VERSION ""

NS_ :

BS_ :

BU_ :

BO_ 1308 Rec_51C: 8 Vector__XXX

BO_ 1436 Rec_59C: 8 Vector__XXX

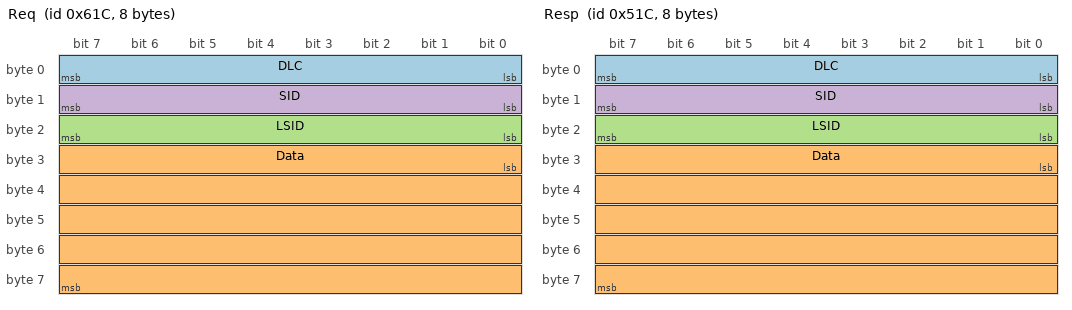
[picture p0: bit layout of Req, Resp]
BO_ 1564 Req: 8 Vector__XXX
  SG_ DLC : 0|8@1- (1,0) [0|1000] "" Vector__XXX
  SG_ Data : 24|40@1+ (1,0) [0|1000] "" Vector__XXX
  SG_ LSID : 16|8@1- (1,0) [0|1000] "" Vector__XXX
  SG_ SID : 8|8@1- (1,0) [0|1000] "" Vector__XXX

BO_ 1564 Req_ERF: 8 Vector__XXX

BO_ 1308 Resp: 8 Vector__XXX
  SG_ DLC : 0|8@1- (1,0) [0|1000] "" Vector__XXX
  SG_ Data : 24|40@1+ (1,0) [0|1000] "" Vector__XXX
  SG_ LSID : 16|8@1- (1,0) [0|1000] "" Vector__XXX
  SG_ SID : 8|8@1- (1,0) [0|1000] "" Vector__XXX

BO_ 32 cycle_ignition_signal1: 8 Vector__XXX

BO_ 367 cycle_ignition_signal2: 8 Vector__XXX

CM_ "This is an example CAN cluster.  The CAN cluster defines what baudrate is used for all nodes on the network.";
CM_ BO_ 1564 "11";
CM_ BO_ 1564 "²Á";
BA_DEF_ "DBName" STRING;
BA_DEF_ "BusType" STRING;
BA_DEF_ BO_ "VFrameFormat" ENUM "StandardCAN","ExtendedCAN","reserved","J1939PG","reserved","reserved","reserved","reserved","reserved","reserved","reserved","reserved","reserved","reserved","StandardCAN_FD","ExtendedCAN_FD";
BA_DEF_ BO_ "GenMsgSendType" ENUM "Cyclic","Event","CyclicIfActive","SpontanWithDelay","CyclicAndSpontan","CyclicAndSpontanWithDelay";
BA_DEF_ BO_ "GenMsgCycleTime" INT 0 0;
BA_DEF_DEF_ "DBName" "Cluster";
BA_DEF_DEF_ "BusType" "CAN";
BA_DEF_DEF_ "VFrameFormat" "StandardCAN";
BA_DEF_DEF_ "GenMsgSendType" "Cyclic";
BA_DEF_DEF_ "GenMsgCycleTime" 0;
BA_ "GenMsgCycleTime" BO_ 1308 100;
BA_ "GenMsgCycleTime" BO_ 1436 100;
BA_ "GenMsgSendType" BO_ 1564 1;
BA_ "GenMsgCycleTime" BO_ 1564 100;
BA_ "GenMsgSendType" BO_ 1308 1;
BA_ "GenMsgCycleTime" BO_ 32 100;
BA_ "GenMsgCycleTime" BO_ 367 100;
